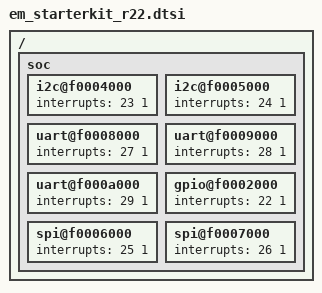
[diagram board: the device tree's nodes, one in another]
/*
 * Copyright (c) 2018 Linaro Limited
 *
 * SPDX-License-Identifier: Apache-2.0
 */

/ {
	soc {
		i2c@f0004000 {
			interrupts = <23 1>;
		};

		i2c@f0005000 {
			interrupts = <24 1>;
		};

		uart@f0008000 {
			interrupts = <27 1>;
		};

		uart@f0009000 {
			interrupts = <28 1>;
		};

		uart@f000a000 {
			interrupts = <29 1>;
		};

		gpio@f0002000 {
			interrupts = <22 1>;
		};

		spi@f0006000 {
			interrupts = <25 1>;
		};

		spi@f0007000 {
			interrupts = <26 1>;
		};
	};
};
